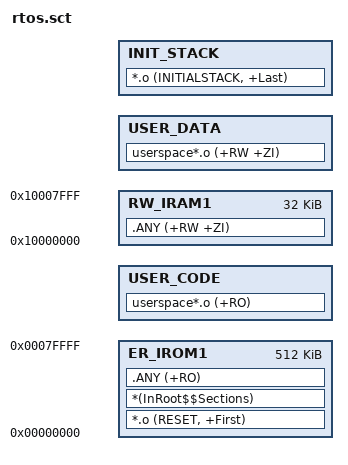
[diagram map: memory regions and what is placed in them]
; *************************************************************
; *** Scatter-Loading Description File generated by uVision ***
; *************************************************************

LR_IROM1 0x00000000 0x00080000  {    ; load region size_region
  ER_IROM1 0x00000000 0x00080000  {  ; load address = execution address
   *.o (RESET, +First)
   *(InRoot$$Sections) ; (not sure what these do... standard library stuff I would imagin...)
   .ANY (+RO)
  }
  USER_CODE +0 { ; Usermode
   userspace*.o (+RO)
  }
  RW_IRAM1 0x10000000 0x00008000  {  ; RW data
   .ANY (+RW +ZI)
  }
  USER_DATA +0 { ; Usermode
   userspace*.o (+RW +ZI)
  }
  INIT_STACK +0 {
   *.o (INITIALSTACK, +Last)
  }
}

